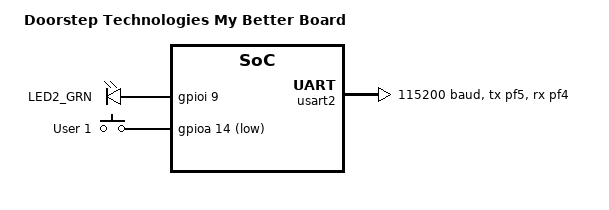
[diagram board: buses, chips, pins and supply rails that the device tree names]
/*
 * Copyright (c) 2024 Antmicro <www.antmicro.com>
 *
 * SPDX-License-Identifier: Apache-2.0
 */

/dts-v1/;
#include <oct/osd32mp15x.dtsi>
#include <zephyr/dt-bindings/input/input-event-codes.h>

/ {
	model = "Doorstep Technologies My Better Board";
	compatible = "doorstep,my-better-board", "oct,osd32mp1-brk";

	chosen {
		zephyr,flash = &retram;
		zephyr,sram = &mcusram;
	};

	leds {
		compatible = "gpio-leds";

		green_led_2: led_1 {
			label = "LED2_GRN";
			gpios = <&gpioi 9 GPIO_ACTIVE_HIGH>;
			status = "okay";
		};
	};

	gpio_keys {
		compatible = "gpio-keys";

		user_button: button {
			label = "User 1";
			gpios = <&gpioa 14 GPIO_ACTIVE_LOW>;
			zephyr,code = <INPUT_KEY_0>;
		};
	};

	aliases {
		led0 = &green_led_2;
		sw0 = &user_button;
	};
};

&usart2 {
	pinctrl-0 = <&usart2_tx_pf5 &usart2_rx_pf4>;
	pinctrl-names = "default";
	current-speed = <115200>;
	status = "okay";
};
